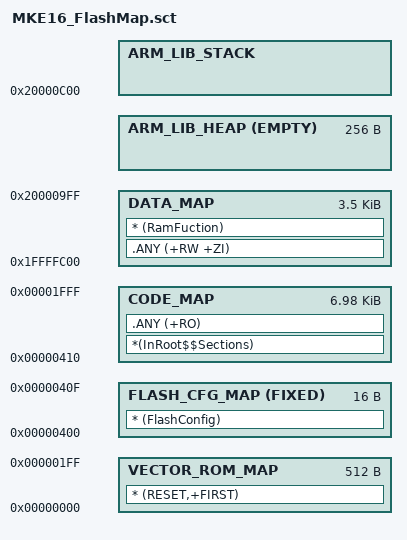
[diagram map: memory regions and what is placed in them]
#! armcc -E
; *************************************************************
; *** Scatter-Loading Description File generated by uVision ***
; *************************************************************


;系统FLASH映射关系表
USER_MAP 0x00000000 0x2000 {    ; load region size_region

  ;ROM空间分配
  VECTOR_ROM_MAP 0x00000000 0x00000200 {	;中断向量表放在FLASH起始地址
	* (RESET,+FIRST)
  }
  
  FLASH_CFG_MAP	0x00000400 FIXED 0x00000010 {		;FLASH配置信息存储在固定位置
	 * (FlashConfig)
  }
  CODE_MAP 0x00000410 0x00001BF0  {  ; load address = execution address
   *(InRoot$$Sections)
   .ANY (+RO)
  }
  
  ;8K SRAM 0x1FFFF800-0x200017FF
  ;4K SRAM 0x1FFFFC00-0x20000BFF
  ;中断向量表映射到RAM中,有定义VECTOR_MATO_RAM时,以下注释打开
  ;VECTOR_RAM_MAP 0x1FFFF800 EMPTY 0x200 {
  
  ;}
  ;RAM空间分配
  ;DATA_MAP 0x1FFFFA00 0x1C00{  ; RW data
  ; .ANY (+RW +ZI)
  ; * (RamFuction)
  ;}
  ;有定义VECTOR_MATO_RAM时,以下注释关闭
  DATA_MAP 0x1FFFFC00 0xE00{  ; RW data
   .ANY (+RW +ZI)
   * (RamFuction)
  }  
  ARM_LIB_HEAP +0 EMPTY 0x0100 {    ; Heap region growing up
  }
  ARM_LIB_STACK 0x20000C00 EMPTY - 0x0100 { ; Stack region growing down
  }
}

